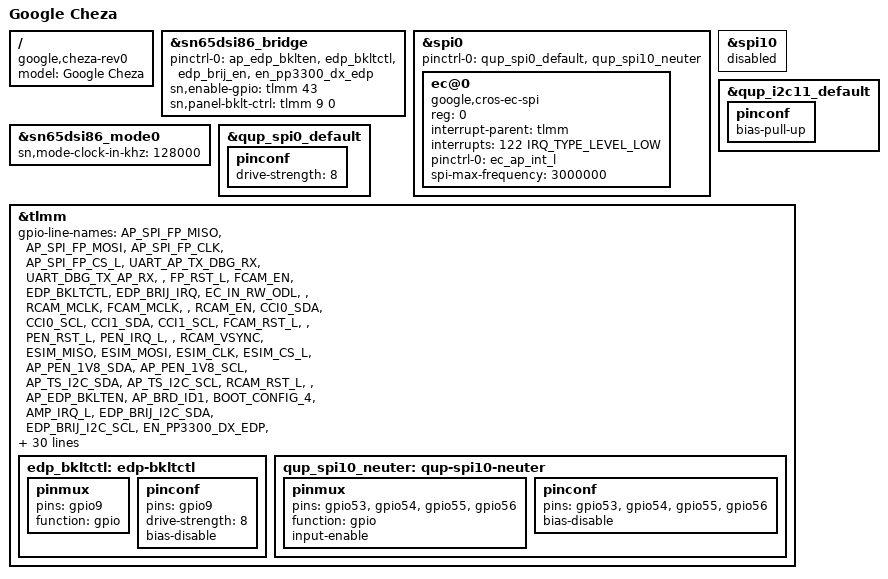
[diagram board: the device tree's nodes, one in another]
// SPDX-License-Identifier: (GPL-2.0+ OR MIT)
/*
 * Google Cheza board device tree source
 *
 * Copyright 2018 Google LLC.
 */

/dts-v1/;

#include "sdm845-cheza.dtsi"

/ {
	model = "Google Cheza";
	compatible = "google,cheza-rev0", "google,cheza", "qcom,sdm845";
};

&sn65dsi86_bridge {
	pinctrl-0 = <&ap_edp_bklten &edp_bkltctl &edp_brij_en
		     &en_pp3300_dx_edp>;
	sn,enable-gpio = <&tlmm 43 0>;  /* TODO: model as regulator? */
	sn,panel-bklt-ctrl = <&tlmm 9 0>;
	/delete-property/clocks;
	/delete-property/clock-names;
};

/*
 * NOTE: spi0 is supposed to be for FP and spi10 is supposed to be for
 * EC.  ...but spi10 was wired incorrectly in -rev0 so we've bluewired
 * things to spi0 (and still left spi10 connected).  Hence a strange
 * pinctrl and the fact that having the EC here doesn't match original
 * schematics.
 */
&spi0 {
	pinctrl-0 = <&qup_spi0_default>, <&qup_spi10_neuter>;
	ec@0 {
		compatible = "google,cros-ec-spi";
		reg = <0>;
		interrupt-parent = <&tlmm>;
		interrupts = <122 IRQ_TYPE_LEVEL_LOW>;
		pinctrl-names = "default";
		pinctrl-0 = <&ec_ap_int_l>;
		spi-max-frequency = <3000000>;
	};
};

&spi10 {
	status = "disabled";
};

&sn65dsi86_mode0 {
	sn,mode-clock-in-khz = <128000>;
};

/* PINCTRL - additions to nodes defined in sdm845.dtsi */

&qup_i2c11_default {
	pinconf {
		/* External pull missing on rev0 */
		/delete-property/bias-disable;
		bias-pull-up;
	};
};

&qup_spi0_default {
	pinconf {
		/* Extra strong since there's a rework (TODO: verify?) */
		drive-strength = <8>;
	};
};

/* PINCTRL - board-specific pinctrl */

&tlmm {
	gpio-line-names = "AP_SPI_FP_MISO",
			  "AP_SPI_FP_MOSI",
			  "AP_SPI_FP_CLK",
			  "AP_SPI_FP_CS_L",
			  "UART_AP_TX_DBG_RX",
			  "UART_DBG_TX_AP_RX",
			  "",
			  "FP_RST_L",
			  "FCAM_EN",
			  "EDP_BKLTCTL",
			  "EDP_BRIJ_IRQ",
			  "EC_IN_RW_ODL",
			  "",
			  "RCAM_MCLK",
			  "FCAM_MCLK",
			  "",
			  "RCAM_EN",
			  "CCI0_SDA",
			  "CCI0_SCL",
			  "CCI1_SDA",
			  "CCI1_SCL",
			  "FCAM_RST_L",
			  "",
			  "PEN_RST_L",
			  "PEN_IRQ_L",
			  "",
			  "RCAM_VSYNC",
			  "ESIM_MISO",
			  "ESIM_MOSI",
			  "ESIM_CLK",
			  "ESIM_CS_L",
			  "AP_PEN_1V8_SDA",
			  "AP_PEN_1V8_SCL",
			  "AP_TS_I2C_SDA",
			  "AP_TS_I2C_SCL",
			  "RCAM_RST_L",
			  "",
			  "AP_EDP_BKLTEN",
			  "AP_BRD_ID1",
			  "BOOT_CONFIG_4",
			  "AMP_IRQ_L",
			  "EDP_BRIJ_I2C_SDA",
			  "EDP_BRIJ_I2C_SCL",
			  "EN_PP3300_DX_EDP",
			  "SD_CD_ODL",
			  "BT_UART_RTS",
			  "BT_UART_CTS",
			  "BT_UART_RXD",
			  "BT_UART_TXD",
			  "AMP_I2C_SDA",
			  "AMP_I2C_SCL",
			  "AP_BRD_ID3",
			  "",
			  "AP_EC_SPI_MISO",
			  "AP_EC_SPI_MOSI",
			  "AP_EC_SPI_CLK",
			  "AP_EC_SPI_CS_L",
			  "FORCED_USB_BOOT",
			  "AMP_BCLK",
			  "AMP_LRCLK",
			  "AMP_DOUT",
			  "AMP_DIN",
			  "AP_BRD_ID2",
			  "PEN_PDCT_L",
			  "HP_MCLK",
			  "HP_BCLK",
			  "HP_LRCLK",
			  "HP_DOUT",
			  "HP_DIN",
			  "",
			  "",
			  "",
			  "",
			  "BT_SLIMBUS_DATA",
			  "BT_SLIMBUS_CLK",
			  "AMP_RESET_L",
			  "",
			  "FCAM_VSYNC",
			  "",
			  "AP_SKU_ID1",
			  "EC_WOV_BCLK",
			  "EC_WOV_LRCLK",
			  "EC_WOV_DOUT",
			  "",
			  "",
			  "AP_H1_SPI_MISO",
			  "AP_H1_SPI_MOSI",
			  "AP_H1_SPI_CLK",
			  "AP_H1_SPI_CS_L",
			  "",
			  "AP_SPI_CS0_L",
			  "AP_SPI_MOSI",
			  "AP_SPI_MISO",
			  "",
			  "",
			  "AP_SPI_CLK",
			  "",
			  "RFFE6_CLK",
			  "RFFE6_DATA",
			  "BOOT_CONFIG_1",
			  "BOOT_CONFIG_2",
			  "BOOT_CONFIG_0",
			  "EDP_BRIJ_EN",
			  "",
			  "USB_HS_TX_EN",
			  "UIM2_DATA",
			  "UIM2_CLK",
			  "UIM2_RST",
			  "UIM2_PRESENT",
			  "UIM1_DATA",
			  "UIM1_CLK",
			  "UIM1_RST",
			  "",
			  "AP_SKU_ID2",
			  "SDM_GRFC_8",
			  "SDM_GRFC_9",
			  "AP_RST_REQ",
			  "HP_IRQ",
			  "TS_RESET_L",
			  "PEN_EJECT_ODL",
			  "HUB_RST_L",
			  "FP_TO_AP_IRQ",
			  "AP_EC_INT_L",
			  "",
			  "",
			  "TS_INT_L",
			  "LTE_PA_THERM2",
			  "SDM_GRFC_3",
			  "LTE_PA_THERM1",
			  "H1_AP_INT_ODL",
			  "QLINK_REQ",
			  "QLINK_EN",
			  "SDM_GRFC_2",
			  "BOOT_CONFIG_3",
			  "WMSS_RESET_L",
			  "SDM_GRFC_0",
			  "SDM_GRFC_1",
			  "RFFE3_DATA",
			  "RFFE3_CLK",
			  "RFFE4_DATA",
			  "RFFE4_CLK",
			  "RFFE5_DATA",
			  "RFFE5_CLK",
			  "GNSS_EN",
			  "WCI2_LTE_COEX_RXD",
			  "WCI2_LTE_COEX_TXD",
			  "AP_RAM_ID1",
			  "AP_RAM_ID2",
			  "RFFE1_DATA",
			  "RFFE1_CLK";

	edp_bkltctl: edp-bkltctl {
		pinmux {
			pins = "gpio9";
			function = "gpio";
		};

		pinconf {
			pins = "gpio9";
			drive-strength = <8>; /* TODO: why? */
			bias-disable;
		};
	};

	qup_spi10_neuter: qup-spi10-neuter {
		pinmux {
			pins = "gpio53", "gpio54", "gpio55", "gpio56";
			function = "gpio";
			input-enable; /* ? */
		};

		pinconf {
			pins = "gpio53", "gpio54", "gpio55", "gpio56";
			bias-disable;
		};
	};
};
